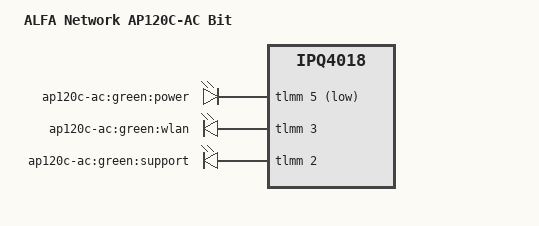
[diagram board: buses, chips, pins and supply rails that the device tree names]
// SPDX-License-Identifier: GPL-2.0-or-later OR MIT

#include "qcom-ipq4018-ap120c-ac.dtsi"

/ {
	model = "ALFA Network AP120C-AC Bit";

	leds {
		compatible = "gpio-leds";

		power {
			label = "ap120c-ac:green:power";
			gpios = <&tlmm 5 GPIO_ACTIVE_LOW>;
			default-state = "on";
		};

		wlan {
			label = "ap120c-ac:green:wlan";
			gpios = <&tlmm 3 GPIO_ACTIVE_HIGH>;
		};

		support {
			label = "ap120c-ac:green:support";
			gpios = <&tlmm 2 GPIO_ACTIVE_HIGH>;
			panic-indicator;
		};
	};
};
